# CH32V00Xxx register map
Vendor: WCH Ltd.; File version: 1.2
Registers are 32-bit, read-write, reset 0x0 unless marked. A register's access mark holds for its fields unless they carry their own. Offsets are from the block's base; [hi:lo] are bit positions; {n}, {i} and the like mark numbered series.

## IWDG — Independent watchdog
Base 0x40003000
0x00 CTLR wo — Key register (IWDG_CTLR)
  [15:0] KEY — Key value
0x04 PSCR — Prescaler register (IWDG_PSCR)
  [2:0] PR — Prescaler divider
0x08 RLDR reset 0xFFF — Reload register (IWDG_RLDR)
  [11:0] RL — Watchdog counter reload value
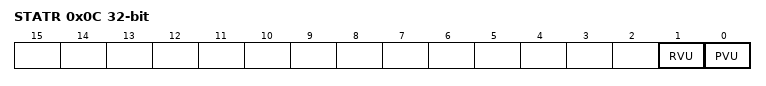
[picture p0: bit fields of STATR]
0x0C STATR ro — Status register (IWDG_SR)
  [1] RVU — Watchdog counter reload value update
  [0] PVU — Watchdog prescaler value update

## WWDG — Window watchdog
Base 0x40002C00
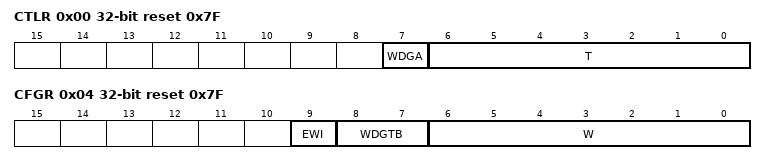
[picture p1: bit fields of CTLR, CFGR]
0x00 CTLR reset 0x7F — Control register (WWDG_CR)
  [7] WDGA — Activation bit
  [6:0] T — 7-bit counter (MSB to LSB)
0x04 CFGR reset 0x7F — Configuration register (WWDG_CFR)
  [9] EWI — Early Wakeup Interrupt
  [8:7] WDGTB — Timer Base
  [6:0] W — 7-bit window value
0x08 STATR — Status register (WWDG_SR)
  [0] EWIF — Early Wakeup Interrupt Flag

## TIM3 — General reduced timer
Base 0x40000800
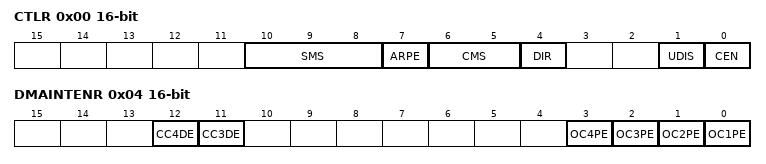
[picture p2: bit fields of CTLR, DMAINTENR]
0x00 CTLR 16-bit — control register
  [10:8] SMS — mode selection
  [7] ARPE — Auto-reload preload enable
  [6:5] CMS — Center-aligned mode selection
  [4] DIR — Direction
  [1] UDIS — Update disable
  [0] CEN — Counter enable
0x04 DMAINTENR 16-bit — DMA enable register
  [12] CC4DE — Compare channel4 DMA request enable
  [11] CC3DE — Compare channel3 DMA request enable
  [n-1] OC{n}PE (n=1..4) — Compare register {n} preload enable
0x08 CNT 16-bit — counter
  [12] CNT — counter value
0x0C ATRLR 16-bit — auto-reload register
  [15:0] ATRLR — Auto-reload value
0x10 CH1CVR 16-bit — compare register 1
  [15:0] CH1CVR — Capture/Compare 1 value
0x14 CH2CVR 16-bit — compare register 2
  [15:0] CH2CVR — Capture/Compare 2 value
0x18 CH3CVR 16-bit — compare register 3
  [15:0] CH3CVR — Compare 3 value
0x1C CH4CVR 16-bit — compare register 4
  [15:0] CH4CVR — Compare 4 value

## I2C1 — Inter integrated circuit
Base 0x40005400
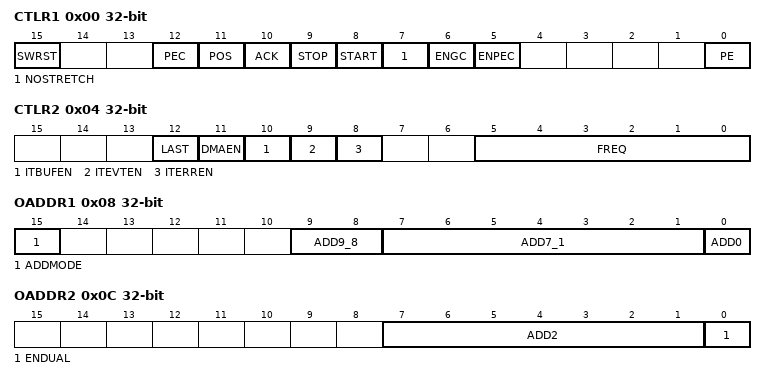
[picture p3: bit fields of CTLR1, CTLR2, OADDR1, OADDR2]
0x00 CTLR1 — Control register 1
  [15] SWRST — Software reset
  [12] PEC — Packet error checking
  [11] POS — Acknowledge/PEC Position (for data reception)
  [10] ACK — Acknowledge enable
  [9] STOP — Stop generation
  [8] START — Start generation
  [7] NOSTRETCH — Clock stretching disable (Slave mode)
  [6] ENGC — General call enable
  [5] ENPEC — PEC enable
  [0] PE — Peripheral enable
0x04 CTLR2 — Control register 2
  [12] LAST — DMA last transfer
  [11] DMAEN — DMA requests enable
  [10] ITBUFEN — Buffer interrupt enable
  [9] ITEVTEN — Event interrupt enable
  [8] ITERREN — Error interrupt enable
  [5:0] FREQ — Peripheral clock frequency
0x08 OADDR1 — Own address register 1
  [15] ADDMODE — Addressing mode (slave mode)
  [9:8] ADD9_8 — Interface address
  [7:1] ADD7_1 — Interface address
  [0] ADD0 — Interface address
0x0C OADDR2 — Own address register 2
  [7:1] ADD2 — Interface address
  [0] ENDUAL — Dual addressing mode enable
0x10 DATAR — Data register
  [7:0] DATAR — 8-bit data register
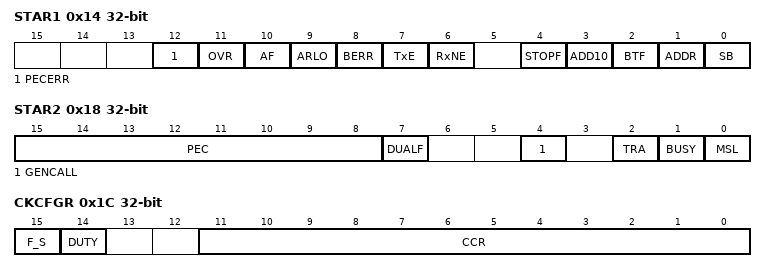
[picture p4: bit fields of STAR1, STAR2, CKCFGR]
0x14 STAR1 access per field — Status register 1
  [12] PECERR rw — PEC Error in reception
  [11] OVR rw — Overrun/Underrun
  [10] AF rw — Acknowledge failure
  [9] ARLO rw — Arbitration lost (master mode)
  [8] BERR rw — Bus error
  [7] TxE ro — Data register empty (transmitters)
  [6] RxNE ro — Data register not empty (receivers)
  [4] STOPF ro — Stop detection (slave mode)
  [3] ADD10 ro — 10-bit header sent (Master mode)
  [2] BTF ro — Byte transfer finished
  [1] ADDR ro — Address sent (master mode)/matched (slave mode)
  [0] SB ro — Start bit (Master mode)
0x18 STAR2 ro — Status register 2
  [15:8] PEC — acket error checking register
  [7] DUALF — Dual flag (Slave mode)
  [4] GENCALL — General call address (Slave mode)
  [2] TRA — Transmitter/receiver
  [1] BUSY — Bus busy
  [0] MSL — Master/slave
0x1C CKCFGR — Clock control register
  [15] F_S — I2C master mode selection
  [14] DUTY — Fast mode duty cycle
  [11:0] CCR — Clock control register in Fast/Standard mode (Master mode)
